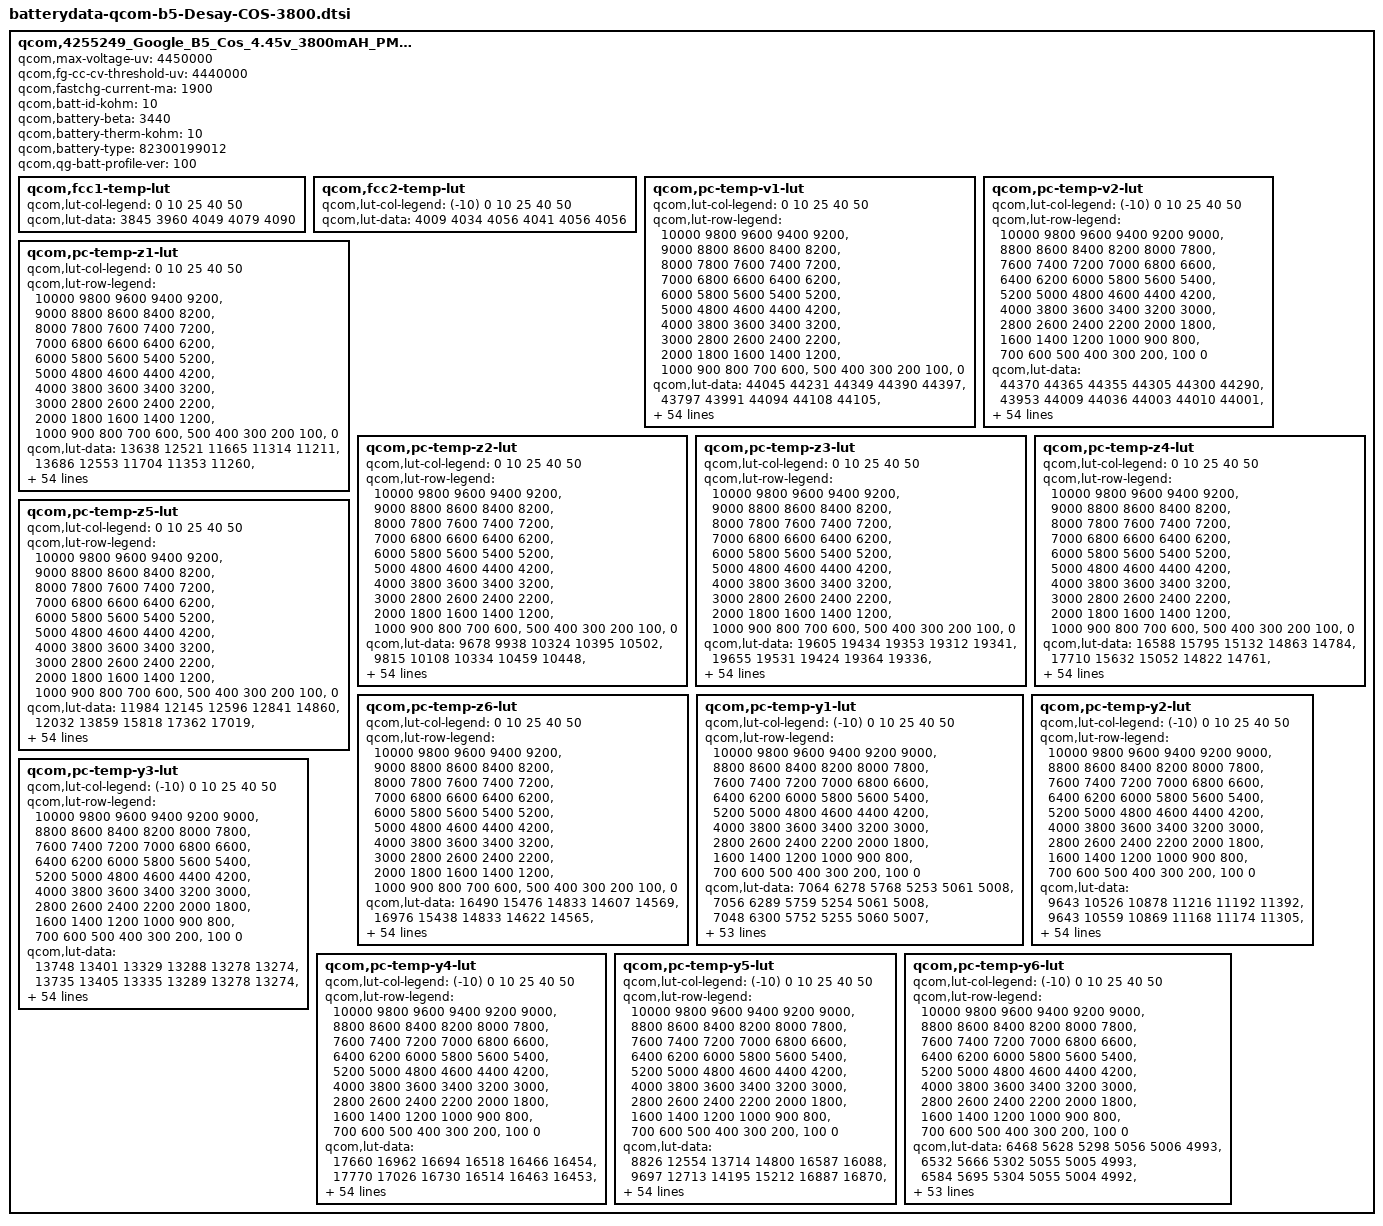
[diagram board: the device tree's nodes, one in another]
// SPDX-License-Identifier: GPL-2.0
qcom,4255249_Google_B5_Cos_4.45v_3800mAH_PM7250 {
	/* 4255249_Google_B5_Cos_4.45v_3800mAH_PM7250_Nov26th2019 */
	qcom,max-voltage-uv = <4450000>;
	qcom,fg-cc-cv-threshold-uv = <4440000>;
	qcom,fastchg-current-ma = <1900>;
	qcom,batt-id-kohm = <10>;
	qcom,battery-beta = <3440>;
	qcom,battery-therm-kohm = <10>;
	qcom,battery-type = "82300199012";
	qcom,qg-batt-profile-ver = <100>;

	qcom,fcc1-temp-lut {
		qcom,lut-col-legend = <0 10 25 40 50>;
		qcom,lut-data = <3845 3960 4049 4079 4090>;
	};

	qcom,fcc2-temp-lut {
		qcom,lut-col-legend = <(-10) 0 10 25 40 50>;
		qcom,lut-data = <4009 4034 4056 4041 4056 4056>;
	};

	qcom,pc-temp-v1-lut {
		qcom,lut-col-legend = <0 10 25 40 50>;
		qcom,lut-row-legend = <10000 9800 9600 9400 9200>,
			<9000 8800 8600 8400 8200>,
			<8000 7800 7600 7400 7200>,
			<7000 6800 6600 6400 6200>,
			<6000 5800 5600 5400 5200>,
			<5000 4800 4600 4400 4200>,
			<4000 3800 3600 3400 3200>,
			<3000 2800 2600 2400 2200>,
			<2000 1800 1600 1400 1200>,
			<1000 900 800 700 600>,
			<500 400 300 200 100>,
			<0>;
		qcom,lut-data = <44045 44231 44349 44390 44397>,
			<43797 43991 44094 44108 44105>,
			<43529 43751 43865 43874 43866>,
			<43256 43518 43644 43656 43645>,
			<42987 43281 43411 43432 43430>,
			<42721 43037 43172 43199 43202>,
			<42465 42786 42927 42960 42966>,
			<42222 42536 42675 42715 42721>,
			<41986 42287 42424 42467 42473>,
			<41755 42041 42173 42219 42226>,
			<41531 41801 41925 41971 41981>,
			<41315 41564 41685 41728 41739>,
			<41108 41338 41450 41489 41498>,
			<40902 41122 41224 41256 41262>,
			<40685 40906 41005 41028 41034>,
			<40470 40684 40790 40808 40812>,
			<40268 40462 40571 40594 40600>,
			<40076 40260 40359 40389 40397>,
			<39901 40073 40168 40198 40204>,
			<39747 39896 39990 40020 40021>,
			<39605 39731 39819 39842 39840>,
			<39465 39572 39660 39663 39659>,
			<39329 39419 39474 39474 39471>,
			<39200 39266 39191 39241 39246>,
			<39078 39096 38927 39001 39009>,
			<38961 38889 38794 38837 38839>,
			<38846 38702 38704 38717 38710>,
			<38735 38562 38614 38607 38597>,
			<38634 38450 38526 38501 38491>,
			<38539 38377 38442 38404 38394>,
			<38455 38326 38363 38318 38305>,
			<38381 38282 38291 38240 38223>,
			<38314 38241 38230 38172 38150>,
			<38260 38205 38177 38112 38084>,
			<38218 38172 38130 38057 38024>,
			<38180 38142 38089 38010 37969>,
			<38144 38106 38046 37961 37912>,
			<38109 38066 38002 37907 37843>,
			<38063 38015 37950 37844 37765>,
			<38001 37937 37872 37764 37680>,
			<37921 37831 37763 37659 37584>,
			<37806 37716 37642 37542 37473>,
			<37663 37580 37504 37407 37335>,
			<37510 37424 37347 37256 37182>,
			<37372 37270 37190 37101 37029>,
			<37255 37161 37094 37009 36945>,
			<37217 37131 37068 36986 36921>,
			<37173 37105 37050 36968 36905>,
			<37134 37075 37033 36952 36890>,
			<37084 37036 36993 36909 36838>,
			<36928 36847 36785 36687 36596>,
			<36520 36422 36354 36247 36150>,
			<35944 35834 35775 35671 35577>,
			<35140 35022 34984 34885 34788>,
			<33788 33673 33752 33675 33561>,
			<30000 30000 30000 30000 30000>;
	};

	qcom,pc-temp-v2-lut {
		qcom,lut-col-legend = <(-10) 0 10 25 40 50>;
		qcom,lut-row-legend = <10000 9800 9600 9400 9200 9000>,
			<8800 8600 8400 8200 8000 7800>,
			<7600 7400 7200 7000 6800 6600>,
			<6400 6200 6000 5800 5600 5400>,
			<5200 5000 4800 4600 4400 4200>,
			<4000 3800 3600 3400 3200 3000>,
			<2800 2600 2400 2200 2000 1800>,
			<1600 1400 1200 1000 900 800>,
			<700 600 500 400 300 200>,
			<100 0>;
		qcom,lut-data = <44370 44365 44355 44305 44300 44290>,
			<43953 44009 44036 44003 44010 44001>,
			<43599 43692 43747 43727 43743 43733>,
			<43327 43423 43492 43479 43499 43490>,
			<43111 43191 43267 43258 43277 43268>,
			<42878 42950 43031 43027 43046 43037>,
			<42610 42692 42781 42781 42803 42796>,
			<42343 42434 42529 42534 42557 42551>,
			<42101 42182 42279 42287 42310 42305>,
			<41865 41935 42031 42040 42063 42059>,
			<41601 41697 41788 41797 41820 41816>,
			<41305 41468 41548 41558 41579 41575>,
			<41044 41240 41314 41323 41344 41340>,
			<40851 41011 41086 41092 41112 41109>,
			<40655 40782 40864 40868 40887 40884>,
			<40367 40548 40651 40654 40671 40666>,
			<40019 40312 40441 40446 40462 40455>,
			<39750 40067 40222 40242 40260 40254>,
			<39545 39811 39995 40043 40065 40063>,
			<39352 39575 39764 39843 39875 39876>,
			<39166 39366 39525 39648 39698 39702>,
			<38977 39172 39297 39445 39508 39514>,
			<38748 38990 39099 39213 39263 39269>,
			<38490 38819 38918 38973 39004 39009>,
			<38323 38660 38758 38792 38821 38826>,
			<38224 38513 38614 38649 38682 38686>,
			<38147 38373 38485 38526 38559 38562>,
			<38078 38224 38369 38418 38447 38449>,
			<38018 38092 38262 38321 38346 38348>,
			<37958 38004 38164 38229 38251 38252>,
			<37899 37938 38072 38143 38165 38164>,
			<37839 37878 37982 38064 38088 38084>,
			<37779 37825 37892 37990 38019 38012>,
			<37717 37774 37822 37920 37952 37942>,
			<37653 37727 37776 37852 37886 37880>,
			<37588 37681 37733 37784 37815 37808>,
			<37520 37630 37687 37717 37722 37700>,
			<37447 37574 37639 37648 37616 37568>,
			<37372 37508 37582 37573 37521 37462>,
			<37295 37426 37517 37492 37432 37371>,
			<37218 37333 37433 37414 37353 37293>,
			<37144 37226 37326 37327 37266 37206>,
			<37066 37100 37202 37194 37140 37080>,
			<36986 36977 37057 37070 37016 36955>,
			<36897 36854 36901 36908 36863 36808>,
			<36796 36750 36805 36865 36832 36779>,
			<36742 36701 36766 36850 36817 36765>,
			<36681 36653 36728 36832 36798 36746>,
			<36611 36602 36677 36806 36770 36717>,
			<36502 36518 36590 36735 36688 36622>,
			<36338 36356 36388 36484 36396 36301>,
			<36054 36008 35947 35994 35891 35792>,
			<35595 35422 35293 35343 35229 35119>,
			<34848 34493 34418 34442 34296 34177>,
			<33531 32882 32962 32987 32849 32711>,
			<30961 29505 28446 28011 28363 28341>;
	};

	qcom,pc-temp-z1-lut {
		qcom,lut-col-legend = <0 10 25 40 50>;
		qcom,lut-row-legend = <10000 9800 9600 9400 9200>,
			<9000 8800 8600 8400 8200>,
			<8000 7800 7600 7400 7200>,
			<7000 6800 6600 6400 6200>,
			<6000 5800 5600 5400 5200>,
			<5000 4800 4600 4400 4200>,
			<4000 3800 3600 3400 3200>,
			<3000 2800 2600 2400 2200>,
			<2000 1800 1600 1400 1200>,
			<1000 900 800 700 600>,
			<500 400 300 200 100>,
			<0>;
		qcom,lut-data = <13638 12521 11665 11314 11211>,
			<13686 12553 11704 11353 11260>,
			<13680 12525 11695 11352 11263>,
			<13682 12515 11676 11347 11258>,
			<13679 12516 11662 11336 11254>,
			<13662 12510 11654 11331 11253>,
			<13640 12489 11644 11328 11251>,
			<13601 12466 11632 11327 11250>,
			<13574 12445 11628 11325 11249>,
			<13571 12426 11628 11323 11248>,
			<13570 12414 11628 11321 11248>,
			<13552 12406 11627 11320 11247>,
			<13476 12403 11626 11320 11247>,
			<13396 12402 11626 11320 11247>,
			<13333 12401 11629 11320 11247>,
			<13285 12399 11630 11320 11247>,
			<13279 12397 11627 11319 11248>,
			<13283 12400 11624 11319 11248>,
			<13284 12409 11625 11319 11249>,
			<13271 12415 11629 11321 11250>,
			<13253 12420 11634 11323 11252>,
			<13246 12424 11641 11325 11252>,
			<13251 12433 11646 11327 11253>,
			<13261 12445 11648 11330 11255>,
			<13285 12456 11650 11333 11258>,
			<13306 12467 11655 11337 11261>,
			<13305 12474 11663 11340 11264>,
			<13293 12476 11669 11344 11266>,
			<13287 12478 11674 11348 11269>,
			<13300 12485 11679 11352 11271>,
			<13319 12501 11683 11355 11274>,
			<13334 12509 11687 11358 11277>,
			<13349 12508 11692 11362 11280>,
			<13356 12507 11699 11365 11282>,
			<13357 12520 11707 11369 11285>,
			<13362 12553 11716 11374 11289>,
			<13389 12578 11724 11379 11293>,
			<13430 12600 11733 11383 11296>,
			<13453 12617 11743 11388 11299>,
			<13469 12625 11748 11391 11302>,
			<13486 12631 11753 11395 11304>,
			<13498 12635 11759 11400 11307>,
			<13504 12646 11765 11408 11309>,
			<13502 12650 11773 11411 11311>,
			<13523 12654 11782 11411 11313>,
			<13490 12645 11789 11412 11313>,
			<13517 12672 11786 11413 11314>,
			<13541 12652 11786 11415 11315>,
			<13500 12654 11789 11415 11317>,
			<13526 12672 11795 11421 11320>,
			<13530 12688 11815 11426 11325>,
			<13524 12740 11824 11433 11331>,
			<13566 12737 11846 11445 11340>,
			<13578 12795 11876 11462 11354>,
			<13578 12795 11876 11462 11354>,
			<13578 12795 11876 11462 11354>;
	};

	qcom,pc-temp-z2-lut {
		qcom,lut-col-legend = <0 10 25 40 50>;
		qcom,lut-row-legend = <10000 9800 9600 9400 9200>,
			<9000 8800 8600 8400 8200>,
			<8000 7800 7600 7400 7200>,
			<7000 6800 6600 6400 6200>,
			<6000 5800 5600 5400 5200>,
			<5000 4800 4600 4400 4200>,
			<4000 3800 3600 3400 3200>,
			<3000 2800 2600 2400 2200>,
			<2000 1800 1600 1400 1200>,
			<1000 900 800 700 600>,
			<500 400 300 200 100>,
			<0>;
		qcom,lut-data = <9678 9938 10324 10395 10502>,
			<9815 10108 10334 10459 10448>,
			<9875 10214 10414 10407 10418>,
			<9903 10210 10406 10404 10435>,
			<9910 10183 10361 10489 10342>,
			<9915 10181 10302 10458 10319>,
			<9922 10202 10266 10426 10312>,
			<9939 10210 10237 10381 10318>,
			<9953 10197 10228 10342 10330>,
			<9954 10175 10249 10326 10344>,
			<9955 10156 10274 10315 10362>,
			<9954 10135 10284 10323 10372>,
			<9950 10112 10291 10336 10375>,
			<9947 10086 10299 10345 10375>,
			<9947 10066 10316 10351 10384>,
			<9947 10058 10334 10357 10398>,
			<9948 10056 10349 10369 10413>,
			<9951 10115 10364 10385 10432>,
			<9952 10294 10379 10402 10449>,
			<9946 10363 10395 10424 10465>,
			<9936 10244 10411 10433 10476>,
			<9931 10139 10432 10430 10481>,
			<9928 10157 10447 10427 10485>,
			<9925 10189 10455 10432 10501>,
			<9926 10225 10459 10445 10525>,
			<9934 10273 10441 10459 10514>,
			<9949 10304 10401 10478 10430>,
			<9979 10311 10400 10484 10375>,
			<10003 10315 10451 10463 10354>,
			<10022 10315 10480 10441 10344>,
			<10041 10310 10474 10421 10350>,
			<10064 10307 10465 10396 10368>,
			<10089 10306 10467 10397 10394>,
			<10100 10304 10476 10416 10438>,
			<10099 10308 10490 10447 10486>,
			<10095 10318 10515 10519 10542>,
			<10082 10327 10542 10581 10593>,
			<10055 10340 10566 10612 10631>,
			<10038 10352 10588 10640 10663>,
			<10034 10359 10612 10658 10674>,
			<10038 10365 10634 10693 10680>,
			<10048 10368 10638 10709 10683>,
			<10060 10369 10623 10714 10701>,
			<10073 10369 10629 10706 10707>,
			<9935 10386 10658 10675 10706>,
			<9693 10470 10665 10717 10744>,
			<9455 10398 10659 10716 10751>,
			<9418 10336 10606 10698 10724>,
			<9444 10334 10593 10737 10783>,
			<9426 10463 10642 10805 10833>,
			<9443 10361 10696 10744 10692>,
			<9384 10269 10637 10642 10537>,
			<9324 10154 10589 10560 10498>,
			<9412 9969 10517 10463 10432>,
			<9412 9969 10517 10463 10432>,
			<9412 9969 10517 10463 10432>;
	};

	qcom,pc-temp-z3-lut {
		qcom,lut-col-legend = <0 10 25 40 50>;
		qcom,lut-row-legend = <10000 9800 9600 9400 9200>,
			<9000 8800 8600 8400 8200>,
			<8000 7800 7600 7400 7200>,
			<7000 6800 6600 6400 6200>,
			<6000 5800 5600 5400 5200>,
			<5000 4800 4600 4400 4200>,
			<4000 3800 3600 3400 3200>,
			<3000 2800 2600 2400 2200>,
			<2000 1800 1600 1400 1200>,
			<1000 900 800 700 600>,
			<500 400 300 200 100>,
			<0>;
		qcom,lut-data = <19605 19434 19353 19312 19341>,
			<19655 19531 19424 19364 19336>,
			<19663 19629 19440 19366 19342>,
			<19672 19656 19473 19369 19346>,
			<19687 19664 19486 19399 19365>,
			<19711 19661 19487 19401 19365>,
			<19727 19648 19486 19401 19366>,
			<19738 19634 19479 19392 19364>,
			<19743 19620 19473 19381 19360>,
			<19742 19607 19465 19375 19356>,
			<19740 19600 19456 19370 19351>,
			<19737 19593 19447 19366 19348>,
			<19731 19587 19438 19362 19347>,
			<19723 19580 19432 19360 19346>,
			<19714 19573 19428 19358 19344>,
			<19704 19567 19425 19357 19342>,
			<19695 19562 19423 19357 19338>,
			<19687 19563 19421 19357 19333>,
			<19678 19572 19419 19356 19331>,
			<19668 19573 19416 19348 19331>,
			<19658 19551 19414 19345 19331>,
			<19650 19529 19411 19350 19332>,
			<19644 19525 19410 19355 19333>,
			<19639 19523 19420 19353 19334>,
			<19642 19525 19430 19347 19335>,
			<19651 19544 19424 19350 19340>,
			<19664 19558 19408 19363 19356>,
			<19686 19557 19405 19372 19363>,
			<19701 19555 19409 19378 19360>,
			<19712 19552 19415 19382 19355>,
			<19723 19544 19424 19379 19352>,
			<19727 19538 19433 19373 19349>,
			<19728 19533 19432 19368 19346>,
			<19725 19528 19428 19365 19342>,
			<19721 19524 19424 19361 19339>,
			<19715 19519 19420 19358 19334>,
			<19705 19517 19416 19355 19331>,
			<19691 19516 19414 19353 19333>,
			<19676 19515 19412 19352 19336>,
			<19656 19512 19409 19351 19335>,
			<19639 19507 19405 19350 19331>,
			<19632 19503 19403 19349 19330>,
			<19625 19498 19402 19348 19331>,
			<19610 19492 19400 19348 19332>,
			<19515 19475 19396 19345 19334>,
			<19399 19443 19378 19336 19321>,
			<19299 19412 19374 19332 19321>,
			<19290 19376 19368 19332 19318>,
			<19291 19358 19358 19328 19310>,
			<19287 19316 19356 19325 19310>,
			<19281 19349 19352 19333 19325>,
			<19297 19353 19354 19339 19333>,
			<19298 19348 19348 19342 19328>,
			<19423 19360 19345 19346 19329>,
			<19423 19360 19345 19346 19329>,
			<19423 19360 19345 19346 19329>;
	};

	qcom,pc-temp-z4-lut {
		qcom,lut-col-legend = <0 10 25 40 50>;
		qcom,lut-row-legend = <10000 9800 9600 9400 9200>,
			<9000 8800 8600 8400 8200>,
			<8000 7800 7600 7400 7200>,
			<7000 6800 6600 6400 6200>,
			<6000 5800 5600 5400 5200>,
			<5000 4800 4600 4400 4200>,
			<4000 3800 3600 3400 3200>,
			<3000 2800 2600 2400 2200>,
			<2000 1800 1600 1400 1200>,
			<1000 900 800 700 600>,
			<500 400 300 200 100>,
			<0>;
		qcom,lut-data = <16588 15795 15132 14863 14784>,
			<17710 15632 15052 14822 14761>,
			<17563 15892 14924 14765 14730>,
			<17330 15831 15003 14739 14706>,
			<16989 15536 14999 14818 14776>,
			<16551 15353 14901 14778 14753>,
			<16218 15226 14840 14748 14731>,
			<15957 15127 14797 14732 14717>,
			<15749 15051 14768 14721 14707>,
			<15589 14988 14749 14713 14701>,
			<15460 14931 14736 14707 14696>,
			<15354 14882 14729 14701 14690>,
			<15265 14847 14725 14695 14683>,
			<15194 14822 14718 14689 14676>,
			<15136 14804 14709 14683 14670>,
			<15089 14791 14702 14678 14666>,
			<15053 14780 14697 14670 14663>,
			<15022 14758 14693 14663 14661>,
			<15002 14725 14689 14662 14658>,
			<14989 14713 14685 14662 14652>,
			<14980 14727 14684 14662 14650>,
			<14973 14741 14686 14665 14656>,
			<14968 14742 14692 14671 14667>,
			<14962 14743 14767 14718 14704>,
			<14947 14747 14847 14790 14757>,
			<14928 14782 14847 14793 14760>,
			<14908 14818 14835 14760 14727>,
			<14885 14838 14818 14730 14703>,
			<14869 14854 14793 14707 14692>,
			<14859 14853 14769 14692 14683>,
			<14850 14839 14746 14685 14676>,
			<14845 14825 14729 14681 14670>,
			<14843 14813 14723 14679 14666>,
			<14839 14801 14720 14676 14662>,
			<14833 14789 14720 14676 14661>,
			<14826 14778 14720 14678 14664>,
			<14819 14768 14720 14680 14668>,
			<14813 14759 14721 14684 14674>,
			<14805 14755 14723 14688 14680>,
			<14795 14756 14726 14690 14681>,
			<14785 14758 14730 14693 14680>,
			<14779 14755 14730 14692 14679>,
			<14774 14744 14722 14686 14673>,
			<14759 14735 14715 14684 14671>,
			<14793 14717 14704 14685 14673>,
			<14859 14683 14670 14659 14654>,
			<14963 14706 14662 14653 14646>,
			<14966 14734 14657 14640 14635>,
			<14956 14746 14655 14630 14626>,
			<14949 14782 14653 14630 14625>,
			<14945 14752 14670 14639 14629>,
			<14959 14764 14674 14639 14630>,
			<14986 14785 14681 14636 14634>,
			<14900 14798 14685 14632 14633>,
			<14900 14798 14685 14632 14633>,
			<14900 14798 14685 14632 14633>;
	};

	qcom,pc-temp-z5-lut {
		qcom,lut-col-legend = <0 10 25 40 50>;
		qcom,lut-row-legend = <10000 9800 9600 9400 9200>,
			<9000 8800 8600 8400 8200>,
			<8000 7800 7600 7400 7200>,
			<7000 6800 6600 6400 6200>,
			<6000 5800 5600 5400 5200>,
			<5000 4800 4600 4400 4200>,
			<4000 3800 3600 3400 3200>,
			<3000 2800 2600 2400 2200>,
			<2000 1800 1600 1400 1200>,
			<1000 900 800 700 600>,
			<500 400 300 200 100>,
			<0>;
		qcom,lut-data = <11984 12145 12596 12841 14860>,
			<12032 13859 15818 17362 17019>,
			<12570 14142 18343 19717 19518>,
			<13336 14004 17373 21374 22574>,
			<14196 14413 17120 19556 19456>,
			<15196 14770 17942 20509 19768>,
			<16074 15129 18710 20967 20197>,
			<16865 15491 19493 20723 20864>,
			<17527 15811 20132 20372 21430>,
			<18054 16161 20934 20206 21237>,
			<18489 16716 21521 20112 20695>,
			<18838 17483 21292 20048 20718>,
			<19150 17992 20755 19967 21550>,
			<19328 18337 20745 20089 22211>,
			<19367 18717 21320 20603 22763>,
			<19346 19245 21943 21367 23189>,
			<19274 20131 22667 22679 22833>,
			<19139 22357 23517 24133 21968>,
			<18945 26822 24397 23995 21998>,
			<18427 28575 25376 22545 23335>,
			<17794 26233 26150 22103 24553>,
			<17440 24181 26721 25433 25437>,
			<17183 24883 27788 28407 25949>,
			<17040 26301 33011 25404 23301>,
			<17318 29513 37977 19775 18135>,
			<18075 40224 33931 18359 17488>,
			<19568 47552 24230 18379 19277>,
			<22579 46266 21064 19078 20721>,
			<25287 43165 20614 21690 21461>,
			<27947 40076 20870 24404 22237>,
			<30452 36154 23796 25772 23444>,
			<32307 33466 27744 26871 24991>,
			<33972 31923 29860 28333 26562>,
			<34828 30934 31452 30097 28258>,
			<34816 30517 32328 30738 28796>,
			<34314 30278 32912 30833 28233>,
			<33330 30463 33130 30873 27742>,
			<31808 31835 32814 30295 28228>,
			<30793 33148 32145 29071 29031>,
			<29964 33820 30995 27915 28328>,
			<29616 34288 29298 26675 25392>,
			<30392 34015 28801 26119 24318>,
			<31358 32815 28966 25980 24955>,
			<29969 32024 29022 25472 25112>,
			<21802 31207 29369 24103 24606>,
			<13276 29462 31030 25313 22475>,
			<11402 21893 29096 23818 23321>,
			<11254 15629 27024 26334 24394>,
			<11230 14271 23472 28549 24234>,
			<11162 12547 23443 26764 24667>,
			<11146 14123 19995 24447 27160>,
			<11306 13847 18734 24075 28583>,
			<11180 13183 16908 24940 22943>,
			<12680 13174 15817 26198 22140>,
			<12680 13174 15817 26198 22140>,
			<12680 13174 15817 26198 22140>;
	};

	qcom,pc-temp-z6-lut {
		qcom,lut-col-legend = <0 10 25 40 50>;
		qcom,lut-row-legend = <10000 9800 9600 9400 9200>,
			<9000 8800 8600 8400 8200>,
			<8000 7800 7600 7400 7200>,
			<7000 6800 6600 6400 6200>,
			<6000 5800 5600 5400 5200>,
			<5000 4800 4600 4400 4200>,
			<4000 3800 3600 3400 3200>,
			<3000 2800 2600 2400 2200>,
			<2000 1800 1600 1400 1200>,
			<1000 900 800 700 600>,
			<500 400 300 200 100>,
			<0>;
		qcom,lut-data = <16490 15476 14833 14607 14569>,
			<16976 15438 14833 14622 14565>,
			<16883 15579 14783 14597 14554>,
			<16744 15553 14829 14587 14545>,
			<16575 15414 14832 14636 14585>,
			<16375 15317 14786 14620 14576>,
			<16217 15242 14754 14605 14567>,
			<16089 15181 14730 14593 14559>,
			<15981 15130 14712 14582 14553>,
			<15891 15087 14699 14576 14548>,
			<15815 15051 14689 14570 14543>,
			<15747 15021 14680 14565 14539>,
			<15687 15000 14673 14560 14535>,
			<15631 14986 14666 14556 14531>,
			<15577 14974 14660 14552 14527>,
			<15527 14964 14655 14549 14524>,
			<15490 14954 14651 14546 14521>,
			<15460 14947 14648 14543 14517>,
			<15443 14941 14645 14540 14515>,
			<15435 14937 14643 14537 14512>,
			<15430 14932 14642 14536 14511>,
			<15428 14929 14643 14539 14514>,
			<15427 14929 14646 14546 14520>,
			<15427 14931 14684 14567 14537>,
			<15427 14936 14724 14595 14562>,
			<15427 14963 14722 14598 14566>,
			<15430 14988 14711 14591 14561>,
			<15436 14999 14702 14585 14555>,
			<15443 15007 14695 14580 14549>,
			<15451 15006 14690 14575 14544>,
			<15457 14998 14687 14570 14539>,
			<15461 14991 14684 14566 14535>,
			<15464 14985 14682 14562 14531>,
			<15464 14981 14681 14560 14528>,
			<15463 14977 14680 14558 14526>,
			<15462 14975 14679 14558 14525>,
			<15462 14974 14679 14558 14525>,
			<15463 14975 14680 14559 14528>,
			<15463 14977 14682 14560 14533>,
			<15462 14981 14684 14562 14533>,
			<15461 14985 14686 14563 14531>,
			<15464 14985 14686 14563 14530>,
			<15469 14984 14684 14560 14528>,
			<15467 14982 14682 14560 14529>,
			<15451 14974 14678 14560 14531>,
			<15425 14950 14656 14544 14516>,
			<15419 14944 14651 14539 14512>,
			<15419 14938 14646 14533 14506>,
			<15417 14935 14641 14528 14499>,
			<15421 14937 14641 14527 14498>,
			<15431 14950 14650 14536 14508>,
			<15455 14968 14658 14541 14515>,
			<15484 14989 14664 14544 14516>,
			<15534 15024 14673 14549 14519>,
			<15534 15024 14673 14549 14519>,
			<15534 15024 14673 14549 14519>;
	};

	qcom,pc-temp-y1-lut {
		qcom,lut-col-legend = <(-10) 0 10 25 40 50>;
		qcom,lut-row-legend = <10000 9800 9600 9400 9200 9000>,
			<8800 8600 8400 8200 8000 7800>,
			<7600 7400 7200 7000 6800 6600>,
			<6400 6200 6000 5800 5600 5400>,
			<5200 5000 4800 4600 4400 4200>,
			<4000 3800 3600 3400 3200 3000>,
			<2800 2600 2400 2200 2000 1800>,
			<1600 1400 1200 1000 900 800>,
			<700 600 500 400 300 200>,
			<100 0>;
		qcom,lut-data = <7064 6278 5768 5253 5061 5008>,
			<7056 6289 5759 5254 5061 5008>,
			<7048 6300 5752 5255 5060 5007>,
			<7040 6309 5748 5255 5059 5005>,
			<7034 6316 5746 5254 5058 5004>,
			<7029 6322 5745 5253 5057 5004>,
			<7024 6327 5748 5251 5056 5003>,
			<7021 6329 5750 5249 5055 5003>,
			<7028 6327 5747 5247 5054 5003>,
			<7039 6322 5743 5244 5052 5002>,
			<7036 6317 5743 5243 5051 5001>,
			<7015 6315 5747 5242 5050 5000>,
			<7006 6315 5749 5242 5049 4999>,
			<7012 6312 5748 5241 5047 4999>,
			<7024 6308 5747 5240 5045 4999>,
			<7044 6309 5746 5240 5046 4999>,
			<7072 6312 5747 5239 5047 5000>,
			<7074 6320 5752 5240 5048 5000>,
			<7037 6341 5762 5242 5048 5000>,
			<7013 6351 5765 5243 5048 5000>,
			<7026 6337 5757 5244 5048 5000>,
			<7044 6324 5750 5247 5048 5001>,
			<7048 6329 5750 5250 5049 5001>,
			<7052 6340 5751 5255 5050 5002>,
			<7055 6343 5753 5256 5051 5003>,
			<7061 6342 5758 5256 5052 5004>,
			<7063 6342 5761 5256 5053 5005>,
			<7049 6352 5767 5258 5054 5006>,
			<7030 6362 5772 5260 5056 5007>,
			<7034 6363 5770 5264 5058 5008>,
			<7056 6362 5768 5269 5059 5009>,
			<7063 6364 5769 5273 5061 5011>,
			<7048 6379 5772 5279 5064 5013>,
			<7036 6390 5777 5282 5066 5015>,
			<7038 6390 5791 5283 5069 5016>,
			<7043 6389 5802 5283 5072 5017>,
			<7048 6378 5798 5285 5073 5018>,
			<7071 6351 5788 5288 5075 5020>,
			<7086 6343 5785 5291 5077 5022>,
			<7078 6362 5786 5296 5079 5023>,
			<7061 6376 5786 5296 5081 5024>,
			<7026 6387 5788 5295 5082 5025>,
			<7045 6374 5819 5300 5083 5027>,
			<7131 6406 5819 5306 5086 5028>,
			<7059 6428 5825 5307 5089 5030>,
			<7098 6392 5805 5316 5091 5032>,
			<7145 6405 5826 5315 5090 5032>,
			<7106 6391 5830 5322 5093 5033>,
			<7142 6391 5830 5324 5094 5034>,
			<7178 6412 5816 5325 5095 5036>,
			<7096 6429 5842 5329 5096 5038>,
			<7139 6425 5843 5335 5103 5042>,
			<7223 6462 5849 5355 5114 5050>,
			<7484 6595 5906 5381 5127 5058>,
			<7484 6595 5906 5381 5127 5058>,
			<7484 6595 5906 5381 5127 5058>;
	};

	qcom,pc-temp-y2-lut {
		qcom,lut-col-legend = <(-10) 0 10 25 40 50>;
		qcom,lut-row-legend = <10000 9800 9600 9400 9200 9000>,
			<8800 8600 8400 8200 8000 7800>,
			<7600 7400 7200 7000 6800 6600>,
			<6400 6200 6000 5800 5600 5400>,
			<5200 5000 4800 4600 4400 4200>,
			<4000 3800 3600 3400 3200 3000>,
			<2800 2600 2400 2200 2000 1800>,
			<1600 1400 1200 1000 900 800>,
			<700 600 500 400 300 200>,
			<100 0>;
		qcom,lut-data = <9643 10526 10878 11216 11192 11392>,
			<9643 10559 10869 11168 11174 11305>,
			<9643 10584 10854 11121 11151 11207>,
			<9926 10601 10835 11077 11127 11120>,
			<10231 10611 10811 11039 11106 11061>,
			<10334 10611 10783 11007 11091 11050>,
			<10349 10597 10745 10983 11073 11074>,
			<10362 10586 10717 10958 11052 11092>,
			<10393 10588 10706 10912 11021 11068>,
			<10437 10594 10699 10867 10991 11027>,
			<10480 10604 10698 10866 10993 11010>,
			<10526 10627 10703 10884 11008 10997>,
			<10555 10657 10712 10889 11011 10996>,
			<10569 10700 10731 10875 10976 11021>,
			<10577 10744 10758 10864 10950 11040>,
			<10357 10779 10799 10882 10966 11023>,
			<9848 10808 10848 10923 10995 10996>,
			<9704 10823 10887 10971 10999 10992>,
			<9695 10831 10921 11040 10989 10995>,
			<9689 10834 10935 11078 11002 11001>,
			<9681 10828 10932 11086 11079 11049>,
			<9674 10820 10932 11095 11153 11107>,
			<9670 10815 10956 11122 11179 11144>,
			<9667 10809 10995 11172 11197 11181>,
			<9665 10803 11020 11216 11205 11219>,
			<9663 10792 11039 11260 11230 11261>,
			<9662 10772 11051 11288 11255 11285>,
			<9660 10663 11054 11298 11296 11294>,
			<9659 10506 11052 11302 11339 11304>,
			<9658 10347 11038 11316 11372 11345>,
			<9657 10113 11019 11346 11405 11413>,
			<9656 9953 11024 11360 11447 11458>,
			<9655 9831 11040 11366 11502 11490>,
			<9655 9756 11046 11367 11520 11520>,
			<9655 9721 11028 11344 11495 11557>,
			<9655 9699 10999 11308 11472 11579>,
			<9655 9686 10955 11300 11474 11570>,
			<9655 9678 10896 11297 11479 11552>,
			<9654 9672 10854 11293 11480 11533>,
			<9654 9667 10820 11302 11477 11494>,
			<9654 9664 10753 11298 11473 11530>,
			<9654 9661 10666 11277 11472 11574>,
			<9654 9659 10638 11310 11516 11509>,
			<9654 9658 10582 11239 11480 11495>,
			<9654 9656 10125 11258 11491 11488>,
			<9654 9655 9921 11134 11395 11389>,
			<9654 9654 9812 11106 11374 11358>,
			<9653 9654 9735 11106 11323 11310>,
			<9653 9653 9697 11141 11309 11266>,
			<9653 9653 9676 11145 11289 11280>,
			<9653 9653 9666 11069 11260 11182>,
			<9652 9652 9658 10964 11209 11055>,
			<9651 9651 9654 10848 11057 11018>,
			<9648 9649 9652 10711 10923 10837>,
			<9648 9649 9652 10711 10923 10837>,
			<9648 9649 9652 10711 10923 10837>;
	};

	qcom,pc-temp-y3-lut {
		qcom,lut-col-legend = <(-10) 0 10 25 40 50>;
		qcom,lut-row-legend = <10000 9800 9600 9400 9200 9000>,
			<8800 8600 8400 8200 8000 7800>,
			<7600 7400 7200 7000 6800 6600>,
			<6400 6200 6000 5800 5600 5400>,
			<5200 5000 4800 4600 4400 4200>,
			<4000 3800 3600 3400 3200 3000>,
			<2800 2600 2400 2200 2000 1800>,
			<1600 1400 1200 1000 900 800>,
			<700 600 500 400 300 200>,
			<100 0>;
		qcom,lut-data = <13748 13401 13329 13288 13278 13274>,
			<13735 13405 13335 13289 13278 13274>,
			<13712 13416 13340 13291 13279 13274>,
			<13687 13428 13345 13293 13279 13275>,
			<13668 13437 13349 13294 13279 13275>,
			<13659 13439 13352 13295 13279 13276>,
			<13653 13439 13353 13295 13279 13276>,
			<13650 13439 13354 13295 13279 13276>,
			<13657 13439 13356 13295 13280 13276>,
			<13670 13439 13358 13295 13280 13277>,
			<13657 13441 13358 13295 13280 13277>,
			<13586 13444 13358 13296 13280 13277>,
			<13548 13445 13358 13297 13280 13277>,
			<13544 13440 13357 13297 13280 13277>,
			<13542 13431 13356 13298 13280 13277>,
			<13542 13422 13356 13300 13281 13277>,
			<13546 13412 13356 13303 13285 13276>,
			<13547 13403 13354 13305 13286 13277>,
			<13541 13395 13350 13307 13286 13279>,
			<13537 13386 13345 13307 13287 13281>,
			<13542 13378 13337 13306 13289 13283>,
			<13548 13370 13331 13303 13290 13284>,
			<13539 13364 13327 13300 13286 13281>,
			<13510 13359 13323 13294 13280 13276>,
			<13502 13354 13320 13289 13279 13274>,
			<13523 13349 13318 13284 13279 13274>,
			<13557 13344 13316 13282 13278 13274>,
			<13608 13335 13314 13285 13278 13274>,
			<13678 13326 13313 13289 13277 13274>,
			<13755 13322 13312 13289 13276 13274>,
			<13841 13318 13310 13288 13276 13273>,
			<13933 13321 13307 13287 13276 13273>,
			<14030 13330 13302 13287 13277 13273>,
			<14132 13340 13300 13286 13278 13273>,
			<14239 13352 13304 13285 13277 13274>,
			<14350 13366 13309 13285 13277 13274>,
			<14461 13388 13313 13284 13276 13274>,
			<14573 13433 13317 13284 13276 13272>,
			<14682 13477 13321 13284 13276 13272>,
			<14787 13516 13327 13283 13276 13272>,
			<14884 13571 13330 13285 13275 13273>,
			<14971 13649 13333 13287 13275 13273>,
			<15039 13706 13331 13284 13275 13273>,
			<15015 13753 13332 13285 13276 13273>,
			<15157 13957 13330 13283 13275 13272>,
			<15315 14266 13351 13287 13277 13274>,
			<15414 14469 13371 13289 13276 13275>,
			<15538 14731 13407 13291 13278 13276>,
			<15691 15033 13461 13296 13281 13279>,
			<15913 15304 13543 13300 13282 13279>,
			<16292 15563 13660 13299 13280 13277>,
			<17049 15945 13916 13301 13281 13279>,
			<20492 17277 14706 13310 13284 13280>,
			<39453 28620 16012 13325 13287 13282>,
			<39453 28620 16012 13325 13287 13282>,
			<39453 28620 16012 13325 13287 13282>;
	};

	qcom,pc-temp-y4-lut {
		qcom,lut-col-legend = <(-10) 0 10 25 40 50>;
		qcom,lut-row-legend = <10000 9800 9600 9400 9200 9000>,
			<8800 8600 8400 8200 8000 7800>,
			<7600 7400 7200 7000 6800 6600>,
			<6400 6200 6000 5800 5600 5400>,
			<5200 5000 4800 4600 4400 4200>,
			<4000 3800 3600 3400 3200 3000>,
			<2800 2600 2400 2200 2000 1800>,
			<1600 1400 1200 1000 900 800>,
			<700 600 500 400 300 200>,
			<100 0>;
		qcom,lut-data = <17660 16962 16694 16518 16466 16454>,
			<17770 17026 16730 16514 16463 16453>,
			<17904 17109 16757 16510 16459 16450>,
			<18030 17190 16776 16506 16457 16448>,
			<18119 17247 16787 16503 16456 16446>,
			<18140 17260 16788 16502 16455 16446>,
			<18121 17247 16777 16503 16456 16445>,
			<18092 17234 16766 16504 16457 16445>,
			<18052 17232 16761 16507 16458 16446>,
			<18011 17230 16758 16512 16460 16448>,
			<18007 17232 16760 16516 16462 16450>,
			<18020 17239 16770 16521 16466 16453>,
			<18027 17251 16784 16528 16471 16455>,
			<18026 17275 16804 16537 16478 16459>,
			<18024 17294 16831 16549 16485 16464>,
			<17922 17286 16876 16563 16491 16470>,
			<17674 17263 16920 16580 16497 16478>,
			<17544 17215 16923 16607 16507 16486>,
			<17489 17105 16911 16649 16523 16495>,
			<17432 17022 16888 16677 16546 16508>,
			<17358 16982 16816 16693 16590 16540>,
			<17268 16949 16738 16702 16619 16562>,
			<17120 16911 16688 16644 16571 16529>,
			<16917 16874 16650 16530 16487 16470>,
			<16846 16837 16628 16500 16465 16456>,
			<16837 16800 16612 16495 16458 16452>,
			<16834 16757 16606 16494 16456 16451>,
			<16840 16685 16604 16494 16458 16452>,
			<16852 16627 16602 16495 16462 16453>,
			<16863 16628 16599 16498 16466 16456>,
			<16873 16641 16596 16507 16472 16461>,
			<16882 16658 16583 16514 16479 16468>,
			<16891 16690 16551 16523 16489 16476>,
			<16900 16726 16537 16527 16499 16484>,
			<16908 16768 16545 16525 16509 16496>,
			<16917 16809 16559 16521 16514 16503>,
			<16926 16828 16582 16513 16499 16489>,
			<16936 16842 16615 16498 16469 16461>,
			<16949 16852 16646 16487 16457 16452>,
			<16966 16861 16678 16478 16453 16450>,
			<16985 16862 16694 16482 16458 16454>,
			<17003 16852 16699 16494 16463 16458>,
			<17008 16828 16660 16484 16455 16449>,
			<16959 16808 16642 16490 16459 16453>,
			<16978 16817 16658 16479 16443 16438>,
			<17020 16855 16709 16498 16455 16450>,
			<17053 16905 16750 16512 16467 16459>,
			<17080 16958 16813 16534 16480 16473>,
			<17114 17030 16900 16567 16503 16499>,
			<17149 17119 17021 16601 16514 16501>,
			<17179 17181 17119 16577 16477 16460>,
			<17199 17155 17142 16567 16473 16460>,
			<17632 17172 17252 16609 16494 16472>,
			<23935 20765 17398 16690 16541 16518>,
			<23935 20765 17398 16690 16541 16518>,
			<23935 20765 17398 16690 16541 16518>;
	};

	qcom,pc-temp-y5-lut {
		qcom,lut-col-legend = <(-10) 0 10 25 40 50>;
		qcom,lut-row-legend = <10000 9800 9600 9400 9200 9000>,
			<8800 8600 8400 8200 8000 7800>,
			<7600 7400 7200 7000 6800 6600>,
			<6400 6200 6000 5800 5600 5400>,
			<5200 5000 4800 4600 4400 4200>,
			<4000 3800 3600 3400 3200 3000>,
			<2800 2600 2400 2200 2000 1800>,
			<1600 1400 1200 1000 900 800>,
			<700 600 500 400 300 200>,
			<100 0>;
		qcom,lut-data = <8826 12554 13714 14800 16587 16088>,
			<9697 12713 14195 15212 16887 16870>,
			<10699 13016 14574 15453 16895 17461>,
			<11670 13351 14842 15568 16749 17875>,
			<12445 13606 14992 15602 16590 18130>,
			<12869 13678 15011 15575 16516 18235>,
			<13057 13679 14875 15219 16145 18143>,
			<13246 13680 14715 14785 15790 17951>,
			<13741 13686 14622 14455 15643 17540>,
			<14330 13696 14529 14151 15466 16974>,
			<14244 13819 14343 13948 15216 16626>,
			<13382 14242 14033 13800 14855 16354>,
			<12980 14416 13807 13655 14467 16020>,
			<13987 14312 13640 13453 13971 15572>,
			<15050 14214 13556 13328 13681 15087>,
			<14748 14517 13698 13375 14044 14474>,
			<13937 15155 14062 13503 14646 13926>,
			<13759 15465 14680 13660 14660 13972>,
			<14013 15634 15742 13894 14373 14455>,
			<14381 15733 16223 14290 14284 14923>,
			<15054 15784 16305 15453 14842 15309>,
			<15690 15826 16383 16623 15599 15710>,
			<15026 15942 16643 17113 16215 16312>,
			<12816 16173 16950 17423 16833 16941>,
			<11769 16345 16976 17095 17505 17197>,
			<11472 16482 16919 15285 18317 17366>,
			<11351 16574 16903 14399 18582 17569>,
			<11397 15787 16989 15895 17938 17924>,
			<11495 14678 17116 17547 17149 18175>,
			<11575 13891 17279 17630 16634 17705>,
			<11651 12503 17446 17439 16201 16826>,
			<11701 12037 17167 17365 16375 16527>,
			<11715 11864 15966 17424 17335 16382>,
			<11710 11791 15509 17550 17950 16389>,
			<11718 11985 16391 17762 18144 17428>,
			<11736 12317 17141 18018 18336 18516>,
			<11717 12751 17052 18403 18835 18808>,
			<11658 13469 16818 18781 19581 18999>,
			<11584 13692 16714 18514 20274 19405>,
			<11475 13585 16706 17719 20891 20076>,
			<11433 13541 16431 18250 19853 19847>,
			<11548 13421 16022 18953 18233 19050>,
			<11555 12550 16235 16891 19077 19511>,
			<11524 11952 16141 17327 18726 18673>,
			<11687 11790 13769 16333 20831 21819>,
			<11717 11852 13375 16929 19701 18500>,
			<11795 11711 13042 16670 16982 17868>,
			<11991 11862 12844 16159 16294 16889>,
			<12464 12334 12764 16067 16520 16585>,
			<12654 12674 12863 15634 16246 16181>,
			<12828 12939 12806 15832 16946 17685>,
			<12406 12470 12135 16252 17542 19079>,
			<10854 11287 11381 16337 18439 18322>,
			<9250 9493 11008 16501 18202 18714>,
			<9250 9493 11008 16501 18202 18714>,
			<9250 9493 11008 16501 18202 18714>;
	};

	qcom,pc-temp-y6-lut {
		qcom,lut-col-legend = <(-10) 0 10 25 40 50>;
		qcom,lut-row-legend = <10000 9800 9600 9400 9200 9000>,
			<8800 8600 8400 8200 8000 7800>,
			<7600 7400 7200 7000 6800 6600>,
			<6400 6200 6000 5800 5600 5400>,
			<5200 5000 4800 4600 4400 4200>,
			<4000 3800 3600 3400 3200 3000>,
			<2800 2600 2400 2200 2000 1800>,
			<1600 1400 1200 1000 900 800>,
			<700 600 500 400 300 200>,
			<100 0>;
		qcom,lut-data = <6468 5628 5298 5056 5006 4993>,
			<6532 5666 5302 5055 5005 4993>,
			<6584 5695 5304 5055 5004 4992>,
			<6622 5713 5305 5055 5003 4992>,
			<6643 5723 5305 5055 5003 4992>,
			<6647 5724 5304 5055 5003 4992>,
			<6629 5713 5299 5054 5003 4992>,
			<6608 5700 5293 5054 5004 4992>,
			<6598 5691 5288 5055 5004 4993>,
			<6588 5685 5285 5056 5005 4994>,
			<6566 5684 5284 5057 5006 4994>,
			<6518 5685 5284 5059 5007 4995>,
			<6496 5685 5284 5061 5008 4996>,
			<6495 5683 5287 5064 5010 4997>,
			<6495 5680 5293 5067 5012 4999>,
			<6457 5672 5303 5072 5014 5000>,
			<6364 5658 5314 5079 5018 5002>,
			<6321 5636 5314 5088 5022 5005>,
			<6305 5600 5307 5102 5027 5009>,
			<6293 5572 5296 5110 5034 5014>,
			<6286 5557 5270 5113 5048 5025>,
			<6279 5546 5243 5114 5057 5032>,
			<6252 5534 5227 5096 5040 5020>,
			<6201 5525 5215 5059 5012 4999>,
			<6186 5516 5207 5047 5004 4994>,
			<6216 5508 5202 5042 5002 4992>,
			<6261 5499 5200 5041 5001 4991>,
			<6317 5483 5200 5043 5001 4992>,
			<6388 5469 5201 5046 5002 4992>,
			<6461 5472 5202 5049 5003 4993>,
			<6539 5486 5202 5051 5004 4994>,
			<6617 5505 5200 5053 5007 4996>,
			<6691 5538 5192 5056 5011 4998>,
			<6768 5579 5189 5057 5014 5001>,
			<6850 5626 5196 5057 5017 5005>,
			<6936 5682 5209 5056 5018 5008>,
			<7022 5742 5224 5054 5014 5003>,
			<7109 5808 5243 5051 5005 4994>,
			<7194 5873 5264 5048 5002 4992>,
			<7274 5936 5287 5046 5001 4991>,
			<7350 6009 5307 5049 5002 4993>,
			<7423 6090 5324 5055 5003 4995>,
			<7474 6146 5316 5051 5002 4992>,
			<7452 6191 5322 5054 5004 4994>,
			<7569 6364 5352 5052 4999 4989>,
			<7700 6610 5431 5062 5004 4994>,
			<7781 6775 5488 5068 5007 4998>,
			<7879 6986 5571 5077 5012 5002>,
			<8008 7227 5682 5091 5021 5012>,
			<8187 7459 5825 5105 5026 5013>,
			<8482 7671 5996 5099 5014 5000>,
			<9058 7951 6256 5101 5014 5002>,
			<11729 8924 6913 5127 5024 5007>,
			<26707 17893 7932 5174 5042 5023>,
			<26707 17893 7932 5174 5042 5023>,
			<26707 17893 7932 5174 5042 5023>;
	};

};
